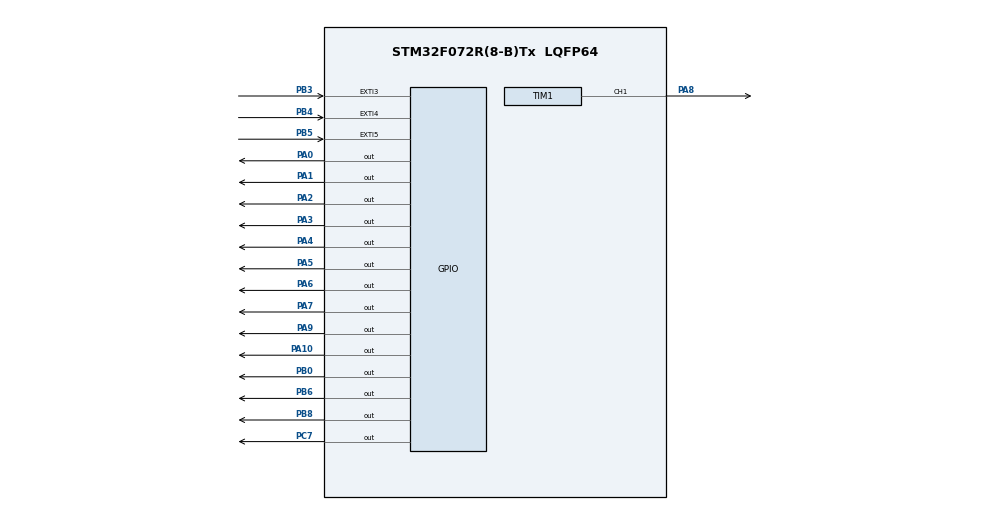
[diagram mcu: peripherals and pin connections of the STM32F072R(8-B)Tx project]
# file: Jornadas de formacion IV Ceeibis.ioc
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Mcu.Family=STM32F0
Mcu.Name=STM32F072R(8-B)Tx
Mcu.Package=LQFP64
NVIC.EXTI2_3_IRQn=true\:0\:0\:false\:false\:true\:true\:true
NVIC.EXTI4_15_IRQn=true\:0\:0\:false\:false\:true\:true\:true
PA0.Signal=GPIO_Output
PA1.Signal=GPIO_Output
PA10.Signal=GPIO_Output
PA13.Mode=Serial_Wire
PA13.Signal=SYS_SWDIO
PA14.Mode=Serial_Wire
PA14.Signal=SYS_SWCLK
PA2.Signal=GPIO_Output
PA3.Signal=GPIO_Output
PA4.Signal=GPIO_Output
PA5.Signal=GPIO_Output
PA6.Signal=GPIO_Output
PA7.Signal=GPIO_Output
PA8.Signal=S_TIM1_CH1
PA9.Signal=GPIO_Output
PB0.Signal=GPIO_Output
PB3.Signal=GPXTI3
PB4.Signal=GPXTI4
PB5.Signal=GPXTI5
PB6.Signal=GPIO_Output
PB8.Signal=GPIO_Output
PC7.Signal=GPIO_Output
ProjectManager.HeapSize=0x200
ProjectManager.StackSize=0x400
ProjectManager.TargetToolchain=TrueSTUDIO
SH.S_TIM1_CH1.0=TIM1_CH1,PWM Generation1 CH1
TIM1.Channel-PWM\ Generation1\ CH1=TIM_CHANNEL_1
TIM1.Period=200
TIM1.Prescaler=66
TIM1.Pulse-PWM\ Generation1\ CH1=100
board=custom

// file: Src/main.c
/* USER CODE BEGIN Header */
/**
 ******************************************************************************
 * @file           : main.c
 * @brief          : Main program body
 ******************************************************************************
 * @attention
 *
 * <h2><center>&copy; Copyright (c) 2019 STMicroelectronics.
 * All rights reserved.</center></h2>
 *
 * This software component is licensed by ST under BSD 3-Clause license,
 * the "License"; You may not use this file except in compliance with the
 * License. You may obtain a copy of the License at:
 *                        opensource.org/licenses/BSD-3-Clause
 *
 ******************************************************************************
 */
/* USER CODE END Header */

#include "main.h"

/* USER CODE BEGIN Includes */
#include <stdlib.h>
#include "simon.h"
/* USER CODE END Includes */

TIM_HandleTypeDef htim1;

void SystemClock_Config(void);
static void MX_GPIO_Init(void);
static void MX_TIM1_Init(void);

/* USER CODE BEGIN 0 */
static void (*_IRQ_BTN_handler)(uint16_t);
/* USER CODE END 0 */

int main(void) {

	/* MCU Configuration--------------------------------------------------------*/

	/* Reset of all peripherals, Initializes the Flash interface and the Systick. */
	HAL_Init();

	/* Configure the system clock */
	SystemClock_Config();

	/* Initialize all configured peripherals */
	MX_GPIO_Init();
	MX_TIM1_Init();

	/* USER CODE BEGIN 2 */
	//LED Test
	HAL_GPIO_WritePin(GPIOB, GPIO_PIN_9, GPIO_PIN_SET);
	HAL_Delay(1000);
	HAL_GPIO_WritePin(GPIOB, GPIO_PIN_9, GPIO_PIN_RESET);
	HAL_GPIO_WritePin(GPIOB, GPIO_PIN_8, GPIO_PIN_SET);
	HAL_Delay(1000);
	HAL_GPIO_WritePin(GPIOB, GPIO_PIN_8, GPIO_PIN_RESET);
	HAL_GPIO_WritePin(GPIOA, GPIO_PIN_5, GPIO_PIN_SET);
	HAL_Delay(1000);
	HAL_GPIO_WritePin(GPIOA, GPIO_PIN_5, GPIO_PIN_RESET);
	simon_t* simon = simon_init(HAL_GetTick());
	_IRQ_BTN_handler = simon->_IRQ_BTN_handler;

	//7 Segment Display Test

	//Buzzer Test

	/* USER CODE END 2 */

	/* Infinite loop */
	while (1) {
		simon_play(simon);
	}
}

void SystemClock_Config(void) {
	RCC_OscInitTypeDef RCC_OscInitStruct = { 0 };
	RCC_ClkInitTypeDef RCC_ClkInitStruct = { 0 };

	/** Initializes the CPU, AHB and APB busses clocks
	 */
	RCC_OscInitStruct.OscillatorType = RCC_OSCILLATORTYPE_HSI;
	RCC_OscInitStruct.HSIState = RCC_HSI_ON;
	RCC_OscInitStruct.HSICalibrationValue = RCC_HSICALIBRATION_DEFAULT;
	RCC_OscInitStruct.PLL.PLLState = RCC_PLL_NONE;
	if (HAL_RCC_OscConfig(&RCC_OscInitStruct) != HAL_OK) {
		Error_Handler();
	}
	/** Initializes the CPU, AHB and APB busses clocks
	 */
	RCC_ClkInitStruct.ClockType = RCC_CLOCKTYPE_HCLK | RCC_CLOCKTYPE_SYSCLK
			| RCC_CLOCKTYPE_PCLK1;
	RCC_ClkInitStruct.SYSCLKSource = RCC_SYSCLKSOURCE_HSI;
	RCC_ClkInitStruct.AHBCLKDivider = RCC_SYSCLK_DIV1;
	RCC_ClkInitStruct.APB1CLKDivider = RCC_HCLK_DIV1;

	if (HAL_RCC_ClockConfig(&RCC_ClkInitStruct, FLASH_LATENCY_0) != HAL_OK) {
		Error_Handler();
	}
}

static void MX_TIM1_Init(void) {

	TIM_MasterConfigTypeDef sMasterConfig = { 0 };
	TIM_OC_InitTypeDef sConfigOC = { 0 };
	TIM_BreakDeadTimeConfigTypeDef sBreakDeadTimeConfig = { 0 };

	htim1.Instance = TIM1;
	htim1.Init.Prescaler = 66;
	htim1.Init.CounterMode = TIM_COUNTERMODE_UP;
	htim1.Init.Period = 200;
	htim1.Init.ClockDivision = TIM_CLOCKDIVISION_DIV1;
	htim1.Init.RepetitionCounter = 0;
	htim1.Init.AutoReloadPreload = TIM_AUTORELOAD_PRELOAD_DISABLE;
	if (HAL_TIM_PWM_Init(&htim1) != HAL_OK) {
		Error_Handler();
	}
	sMasterConfig.MasterOutputTrigger = TIM_TRGO_RESET;
	sMasterConfig.MasterSlaveMode = TIM_MASTERSLAVEMODE_DISABLE;
	if (HAL_TIMEx_MasterConfigSynchronization(&htim1, &sMasterConfig)
			!= HAL_OK) {
		Error_Handler();
	}
	sConfigOC.OCMode = TIM_OCMODE_PWM1;
	sConfigOC.Pulse = 100;
	sConfigOC.OCPolarity = TIM_OCPOLARITY_HIGH;
	sConfigOC.OCNPolarity = TIM_OCNPOLARITY_HIGH;
	sConfigOC.OCFastMode = TIM_OCFAST_DISABLE;
	sConfigOC.OCIdleState = TIM_OCIDLESTATE_RESET;
	sConfigOC.OCNIdleState = TIM_OCNIDLESTATE_RESET;
	if (HAL_TIM_PWM_ConfigChannel(&htim1, &sConfigOC, TIM_CHANNEL_1)
			!= HAL_OK) {
		Error_Handler();
	}
	sBreakDeadTimeConfig.OffStateRunMode = TIM_OSSR_DISABLE;
	sBreakDeadTimeConfig.OffStateIDLEMode = TIM_OSSI_DISABLE;
	sBreakDeadTimeConfig.LockLevel = TIM_LOCKLEVEL_OFF;
	sBreakDeadTimeConfig.DeadTime = 0;
	sBreakDeadTimeConfig.BreakState = TIM_BREAK_DISABLE;
	sBreakDeadTimeConfig.BreakPolarity = TIM_BREAKPOLARITY_HIGH;
	sBreakDeadTimeConfig.AutomaticOutput = TIM_AUTOMATICOUTPUT_DISABLE;
	if (HAL_TIMEx_ConfigBreakDeadTime(&htim1, &sBreakDeadTimeConfig)
			!= HAL_OK) {
		Error_Handler();
	}
	HAL_TIM_MspPostInit(&htim1);

}

static void MX_GPIO_Init(void) {
	GPIO_InitTypeDef GPIO_InitStruct = { 0 };

	/* GPIO Ports Clock Enable */
	__HAL_RCC_GPIOA_CLK_ENABLE()
	;
	__HAL_RCC_GPIOB_CLK_ENABLE()
	;
	__HAL_RCC_GPIOC_CLK_ENABLE()
	;

	/*Configure GPIO pin Output Level */
	HAL_GPIO_WritePin(GPIOA,
			GPIO_PIN_0 | GPIO_PIN_1 | GPIO_PIN_2 | GPIO_PIN_3 | GPIO_PIN_4
					| GPIO_PIN_5 | GPIO_PIN_6 | GPIO_PIN_7 | GPIO_PIN_9,
			GPIO_PIN_RESET);

	/*Configure GPIO pin Output Level */
	HAL_GPIO_WritePin(GPIOB, GPIO_PIN_0 | GPIO_PIN_6 | GPIO_PIN_8 | GPIO_PIN_9,
			GPIO_PIN_RESET);

	/*Configure GPIO pin Output Level */
	HAL_GPIO_WritePin(GPIOC, GPIO_PIN_7, GPIO_PIN_RESET);

	/*Configure GPIO pins : PA0 PA1 PA2 PA3
	 PA4 PA5 PA6 PA7
	 PA9 */
	GPIO_InitStruct.Pin = GPIO_PIN_0 | GPIO_PIN_1 | GPIO_PIN_2 | GPIO_PIN_3
			| GPIO_PIN_4 | GPIO_PIN_5 | GPIO_PIN_6 | GPIO_PIN_7 | GPIO_PIN_9;
	GPIO_InitStruct.Mode = GPIO_MODE_OUTPUT_PP;
	GPIO_InitStruct.Pull = GPIO_NOPULL;
	GPIO_InitStruct.Speed = GPIO_SPEED_FREQ_LOW;
	HAL_GPIO_Init(GPIOA, &GPIO_InitStruct);

	/*Configure GPIO pins : PB0 PB6 PB8 PB9 */
	GPIO_InitStruct.Pin = GPIO_PIN_0 | GPIO_PIN_6 | GPIO_PIN_8 | GPIO_PIN_9;
	GPIO_InitStruct.Mode = GPIO_MODE_OUTPUT_PP;
	GPIO_InitStruct.Pull = GPIO_NOPULL;
	GPIO_InitStruct.Speed = GPIO_SPEED_FREQ_LOW;
	HAL_GPIO_Init(GPIOB, &GPIO_InitStruct);

	/*Configure GPIO pin : PC7 */
	GPIO_InitStruct.Pin = GPIO_PIN_7;
	GPIO_InitStruct.Mode = GPIO_MODE_OUTPUT_PP;
	GPIO_InitStruct.Pull = GPIO_NOPULL;
	GPIO_InitStruct.Speed = GPIO_SPEED_FREQ_LOW;
	HAL_GPIO_Init(GPIOC, &GPIO_InitStruct);

	/*Configure GPIO pins : PB3 PB4 PB5 */
	GPIO_InitStruct.Pin = GPIO_PIN_3 | GPIO_PIN_4 | GPIO_PIN_5;
	GPIO_InitStruct.Mode = GPIO_MODE_IT_RISING;
	GPIO_InitStruct.Pull = GPIO_NOPULL;
	HAL_GPIO_Init(GPIOB, &GPIO_InitStruct);

	/* EXTI interrupt init*/
	HAL_NVIC_SetPriority(EXTI2_3_IRQn, 0, 0);
	HAL_NVIC_EnableIRQ(EXTI2_3_IRQn);

	HAL_NVIC_SetPriority(EXTI4_15_IRQn, 0, 0);
	HAL_NVIC_EnableIRQ(EXTI4_15_IRQn);

}

/* USER CODE BEGIN 4 */
void HAL_GPIO_EXTI_Callback(uint16_t GPIO_Pin) {
	_IRQ_BTN_handler(GPIO_Pin);
}
/* USER CODE END 4 */

void Error_Handler(void) {
}

/************************ (C) COPYRIGHT STMicroelectronics *****END OF FILE****/
